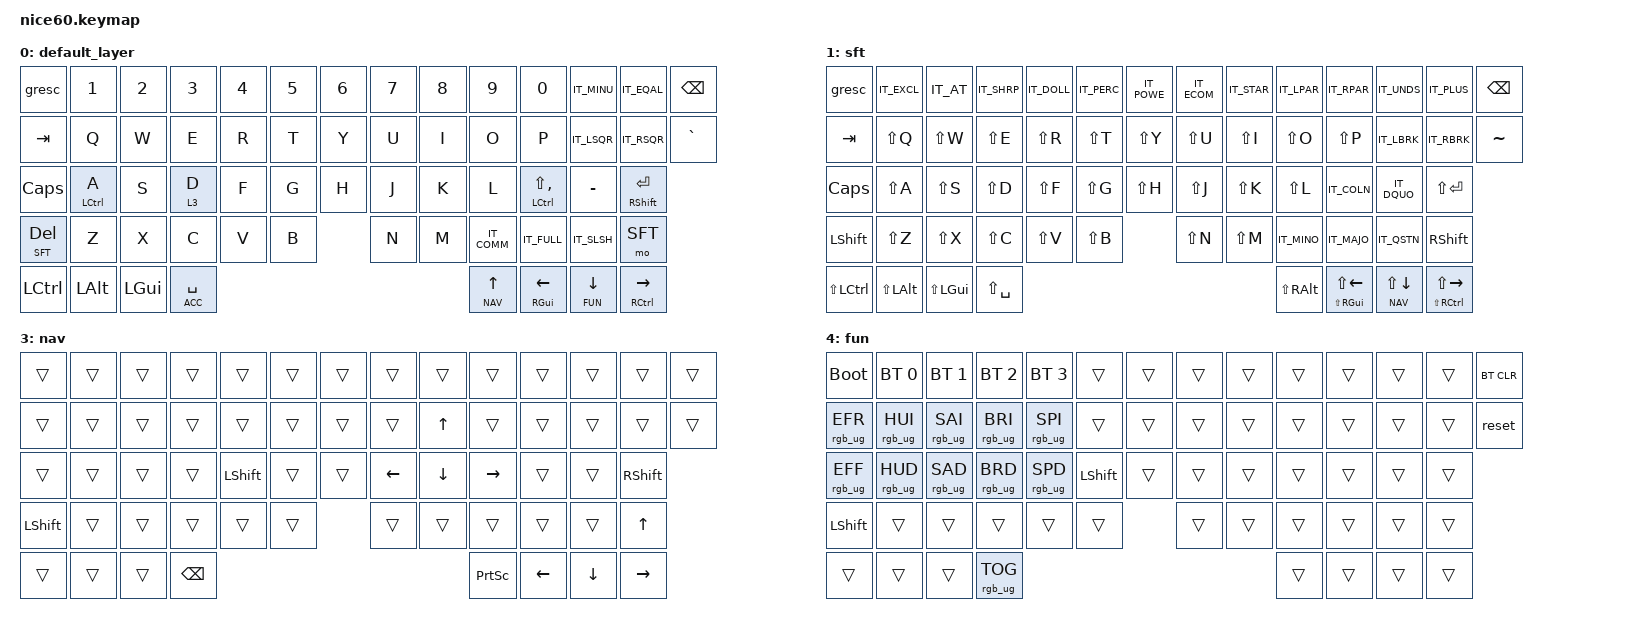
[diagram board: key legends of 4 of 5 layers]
/*
 * Copyright (c) 2021 Nick Winans
 *
 * SPDX-License-Identifier: MIT
 */
 
#include <behaviors.dtsi>
#include <dt-bindings/zmk/keys.h>
#include <dt-bindings/zmk/rgb.h>
#include <dt-bindings/zmk/bt.h>
#include <dt-bindings/zmk/outputs.h>
//#include <dt-bindings/zmk/reset.h>
#include <dt-bindings/zmk/ext_power.h>
#include "ansi_italian_remapping.h"

#define DEFAULT 0
#define SFT     1
#define ACC     2
#define NAV     3
#define FUN     4

/ {

		behaviors {
        hm: homerow_mods {
            compatible = "zmk,behavior-hold-tap";
            label = "HOMEROW_MODS";
            #binding-cells = <2>;
            tapping-term-ms = <250>;
            quick-tap-ms = <0>;
            flavor = "tap-preferred";
            bindings = <&kp>, <&kp>;
        };
    };

	keymap {
		compatible = "zmk,keymap";

    default_layer {
			bindings = <
	&gresc          &kp N1      &kp N2 &kp N3     &kp N4 &kp N5 &kp N6 &kp N7 &kp N8 &kp N9 &kp N0 &kp IT_MINU &kp IT_EQAL  &kp BSPC
	&kp TAB         &kp Q       &kp W  &kp E      &kp R  &kp T  &kp Y  &kp U  &kp I  &kp O  &kp P  &kp IT_LSQR  &kp IT_RSQR  &kp GRAVE
	&kp CLCK        &hm LCTRL A &kp S &lt 3 D &kp F &kp G &kp H &kp J &kp K &kp L &hm LCTRL LS(COMMA) &kp MINUS &mt RSHFT RET
	&lt SFT DEL     &kp Z       &kp X  &kp C      &kp V  &kp B  &kp N  &kp M  &kp IT_COMM &kp IT_FULL &kp IT_SLSH  &mo SFT
	&kp LCTRL &kp LALT &kp LGUI            &lt ACC SPACE                     &lt NAV UP  &mt RGUI LEFT &lt FUN DOWN &mt RCTRL RIGHT
			>;
		};

    sft {
			bindings = <
	&gresc  &kp IT_EXCL &kp IT_AT   &kp IT_SHRP &kp IT_DOLL &kp IT_PERC &kp IT_POWE &kp IT_ECOM &kp IT_STAR &kp IT_LPAR &kp IT_RPAR &kp IT_UNDS &kp IT_PLUS  &kp BSPC
	&kp TAB  &kp LS(Q)  &kp LS(W)  &kp LS(E)  &kp LS(R)  &kp LS(T)  &kp LS(Y) &kp LS(U)  &kp LS(I)  &kp LS(O)  &kp LS(P)  &kp IT_LBRK  &kp IT_RBRK  &kp TILDE
	&kp CLCK  &kp LS(A)  &kp LS(S)  &kp LS(D)  &kp LS(F)  &kp LS(G)  &kp LS(H)  &kp LS(J)  &kp LS(K)  &kp LS(L)  &kp IT_COLN &kp IT_DQUO           &kp LS(RET)
	&kp LSHFT   &kp LS(Z)  &kp LS(X)  &kp LS(C)  &kp LS(V)  &kp LS(B)  &kp LS(N)  &kp LS(M)  &kp IT_MINO &kp IT_MAJO &kp IT_QSTN           &kp RSHFT
	&kp LS(LCTRL) &kp LS(LALT) &kp LS(LGUI)              &kp LS(SPACE)                     &kp LS(RALT)  &mt LS(RGUI) LS(LEFT) &lt NAV LS(DOWN) &mt LS(RCTRL) LS(RIGHT)
			>;
		};

    acc {
			bindings = <
	&trans &kp F1      &kp F2 &kp F3      &kp F4 &kp F5 &kp F6 &kp F7      &kp F8      &kp F9      &kp F10 &kp F11 &kp F12 &trans
	&trans &kp IT_EURO &trans &kp IT_EGRV &trans &trans &trans &kp IT_UGRV &kp IT_IGRV &kp IT_OGRV &trans  &trans  &trans  &trans
	&trans &kp IT_AGRV &trans &trans      &trans &trans &trans &trans      &trans      &trans      &trans  &trans  &trans
	&kp LSHFT  &trans  &trans &trans      &trans &trans &trans &trans      &trans      &trans      &kp RSHFT
	&kp LCTRL &kp LALT &kp LGUI              &kp BSPC                     &kp RALT  &kp LEFT  &kp DOWN    &kp RIGHT
			>;
		};

    nav {
			bindings = <
	&trans    &trans &trans &trans &trans       &trans &trans &trans   &trans   &trans    &trans &trans &trans &trans 
    &trans    &trans &trans &trans &trans       &trans &trans &trans   &kp UP   &trans    &trans &trans &trans &trans 
	&trans    &trans &trans &trans &kp LSHFT    &trans &trans &kp LEFT &kp DOWN &kp RIGHT &trans &trans &kp RSHFT
	&kp LSHFT &trans &trans &trans &trans       &trans &trans &trans   &trans   &trans    &trans &kp UP
	&trans    &trans &trans          &kp BSPC          &kp PSCRN    &kp LEFT  &kp DOWN    &kp RIGHT
			>;
		};

    fun {
			bindings = <
	&bootloader      &bt BT_SEL 0    &bt BT_SEL 1     &bt BT_SEL 2 &bt BT_SEL 3 &trans &trans &trans &trans &trans &trans &trans &trans &bt BT_CLR
    &rgb_ug RGB_EFR  &rgb_ug RGB_HUI  &rgb_ug RGB_SAI &rgb_ug RGB_BRI &rgb_ug RGB_SPI  &trans       &trans       &trans &trans &trans &trans &trans &trans &reset 
	&rgb_ug RGB_EFF  &rgb_ug RGB_HUD  &rgb_ug RGB_SAD &rgb_ug RGB_BRD &rgb_ug RGB_SPD  &kp LSHFT    &trans       &trans &trans &trans &trans &trans &trans 
	&kp LSHFT        &trans          &trans          &trans           &trans       &trans       &trans &trans &trans &trans &trans &trans
	&trans           &trans          &trans          &rgb_ug RGB_TOG  &trans    &trans &trans &trans
			>;
		};
	};
};
